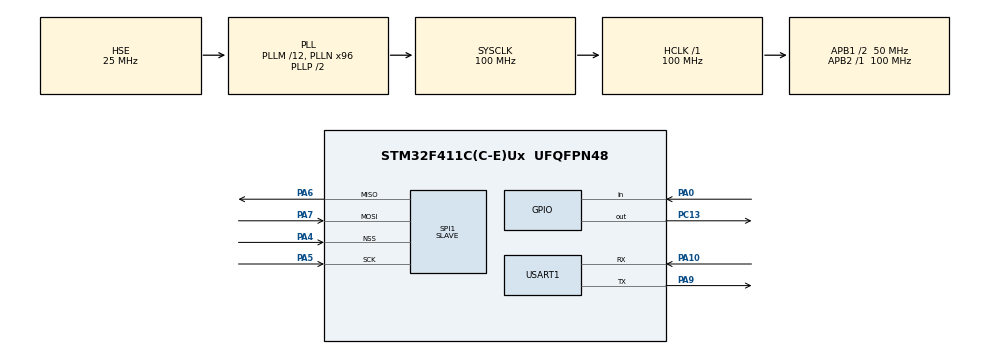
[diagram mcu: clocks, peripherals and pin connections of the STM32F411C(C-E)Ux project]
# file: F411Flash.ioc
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Mcu.Family=STM32F4
Mcu.Name=STM32F411C(C-E)Ux
Mcu.Package=UFQFPN48
NVIC.PriorityGroup=NVIC_PRIORITYGROUP_4
NVIC.TIM4_IRQn=true\:0\:0\:false\:false\:true\:true\:true\:true
PA0-WKUP.Signal=GPIO_Input
PA10.Mode=Asynchronous
PA10.Signal=USART1_RX
PA13.Mode=Serial_Wire
PA13.Signal=SYS_JTMS-SWDIO
PA14.Mode=Serial_Wire
PA14.Signal=SYS_JTCK-SWCLK
PA4.Mode=NSS_Signal_Hard_Input
PA4.Signal=SPI1_NSS
PA5.Mode=Full_Duplex_Slave
PA5.Signal=SPI1_SCK
PA6.Mode=Full_Duplex_Slave
PA6.Signal=SPI1_MISO
PA7.Mode=Full_Duplex_Slave
PA7.Signal=SPI1_MOSI
PA9.Mode=Asynchronous
PA9.Signal=USART1_TX
PC13-ANTI_TAMP.Signal=GPIO_Output
PH0\ -\ OSC_IN.Mode=HSE-External-Oscillator
PH0\ -\ OSC_IN.Signal=RCC_OSC_IN
PH1\ -\ OSC_OUT.Mode=HSE-External-Oscillator
PH1\ -\ OSC_OUT.Signal=RCC_OSC_OUT
ProjectManager.HeapSize=0x200
ProjectManager.StackSize=0x400
ProjectManager.TargetToolchain=STM32CubeIDE
RCC.48MHZClocksFreq_Value=50000000
RCC.AHBFreq_Value=100000000
RCC.APB1CLKDivider=RCC_HCLK_DIV2
RCC.APB1Freq_Value=50000000
RCC.APB1TimFreq_Value=100000000
RCC.APB2Freq_Value=100000000
RCC.APB2TimFreq_Value=100000000
RCC.CortexFreq_Value=100000000
RCC.HCLKFreq_Value=100000000
RCC.HSE_VALUE=25000000
RCC.HSI_VALUE=16000000
RCC.LSE_VALUE=32768
RCC.PLLM=12
RCC.PLLN=96
RCC.PLLSourceVirtual=RCC_PLLSOURCE_HSE
RCC.SYSCLKFreq_VALUE=100000000
RCC.SYSCLKSource=RCC_SYSCLKSOURCE_PLLCLK
RCC.VCOOutputFreq_Value=200000000
SPI1.Direction=SPI_DIRECTION_2LINES
SPI1.Mode=SPI_MODE_SLAVE
SPI1.VirtualNSS=VM_NSSHARD
SPI1.VirtualType=VM_SLAVE
TIM4.Period=1000
TIM4.Prescaler=49999
USART1.VirtualMode=VM_ASYNC
VP_TIM4_VS_ClockSourceINT.Mode=Internal
board=custom

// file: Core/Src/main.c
/* USER CODE BEGIN Header */
/**
  ******************************************************************************
  * @file           : main.c
  * @brief          : Main program body
  ******************************************************************************
  * @attention
  *
  * Copyright (c) 2025 STMicroelectronics.
  * All rights reserved.
  *
  * This software is licensed under terms that can be found in the LICENSE file
  * in the root directory of this software component.
  * If no LICENSE file comes with this software, it is provided AS-IS.
  *
  ******************************************************************************
  */
/* USER CODE END Header */
#include "main.h"

SPI_HandleTypeDef hspi1;

TIM_HandleTypeDef htim4;

UART_HandleTypeDef huart1;

void SystemClock_Config(void);
static void MX_GPIO_Init(void);
static void MX_SPI1_Init(void);
static void MX_USART1_UART_Init(void);
static void MX_TIM4_Init(void);
/* USER CODE BEGIN PFP */
void init();
void loop();
/* USER CODE END PFP */

/* USER CODE BEGIN 0 */
void init()
{
	HAL_TIM_Base_Start_IT(&htim4);
	return;
}

void loop()
{
	return;
}

/* USER CODE END 0 */

int main(void)
{

  /* MCU Configuration--------------------------------------------------------*/

  /* Reset of all peripherals, Initializes the Flash interface and the Systick. */
  HAL_Init();

  /* Configure the system clock */
  SystemClock_Config();

  /* Initialize all configured peripherals */
  MX_GPIO_Init();
  MX_SPI1_Init();
  MX_USART1_UART_Init();
  MX_TIM4_Init();

  /* Infinite loop */
  /* USER CODE BEGIN WHILE */
  init();
  while (1)
  {
	loop();
    /* USER CODE END WHILE */

  }
}

void SystemClock_Config(void)
{
  RCC_OscInitTypeDef RCC_OscInitStruct = {0};
  RCC_ClkInitTypeDef RCC_ClkInitStruct = {0};

  /** Configure the main internal regulator output voltage
  */
  __HAL_RCC_PWR_CLK_ENABLE();
  __HAL_PWR_VOLTAGESCALING_CONFIG(PWR_REGULATOR_VOLTAGE_SCALE1);

  /** Initializes the RCC Oscillators according to the specified parameters
  * in the RCC_OscInitTypeDef structure.
  */
  RCC_OscInitStruct.OscillatorType = RCC_OSCILLATORTYPE_HSE;
  RCC_OscInitStruct.HSEState = RCC_HSE_ON;
  RCC_OscInitStruct.PLL.PLLState = RCC_PLL_ON;
  RCC_OscInitStruct.PLL.PLLSource = RCC_PLLSOURCE_HSE;
  RCC_OscInitStruct.PLL.PLLM = 12;
  RCC_OscInitStruct.PLL.PLLN = 96;
  RCC_OscInitStruct.PLL.PLLP = RCC_PLLP_DIV2;
  RCC_OscInitStruct.PLL.PLLQ = 4;
  if (HAL_RCC_OscConfig(&RCC_OscInitStruct) != HAL_OK)
  {
    Error_Handler();
  }

  /** Initializes the CPU, AHB and APB buses clocks
  */
  RCC_ClkInitStruct.ClockType = RCC_CLOCKTYPE_HCLK|RCC_CLOCKTYPE_SYSCLK
                              |RCC_CLOCKTYPE_PCLK1|RCC_CLOCKTYPE_PCLK2;
  RCC_ClkInitStruct.SYSCLKSource = RCC_SYSCLKSOURCE_PLLCLK;
  RCC_ClkInitStruct.AHBCLKDivider = RCC_SYSCLK_DIV1;
  RCC_ClkInitStruct.APB1CLKDivider = RCC_HCLK_DIV2;
  RCC_ClkInitStruct.APB2CLKDivider = RCC_HCLK_DIV1;

  if (HAL_RCC_ClockConfig(&RCC_ClkInitStruct, FLASH_LATENCY_3) != HAL_OK)
  {
    Error_Handler();
  }
}

static void MX_SPI1_Init(void)
{

  /* SPI1 parameter configuration*/
  hspi1.Instance = SPI1;
  hspi1.Init.Mode = SPI_MODE_SLAVE;
  hspi1.Init.Direction = SPI_DIRECTION_2LINES;
  hspi1.Init.DataSize = SPI_DATASIZE_8BIT;
  hspi1.Init.CLKPolarity = SPI_POLARITY_LOW;
  hspi1.Init.CLKPhase = SPI_PHASE_1EDGE;
  hspi1.Init.NSS = SPI_NSS_HARD_INPUT;
  hspi1.Init.FirstBit = SPI_FIRSTBIT_MSB;
  hspi1.Init.TIMode = SPI_TIMODE_DISABLE;
  hspi1.Init.CRCCalculation = SPI_CRCCALCULATION_DISABLE;
  hspi1.Init.CRCPolynomial = 10;
  if (HAL_SPI_Init(&hspi1) != HAL_OK)
  {
    Error_Handler();
  }

}

static void MX_TIM4_Init(void)
{

  TIM_ClockConfigTypeDef sClockSourceConfig = {0};
  TIM_MasterConfigTypeDef sMasterConfig = {0};

  htim4.Instance = TIM4;
  htim4.Init.Prescaler = 49999;
  htim4.Init.CounterMode = TIM_COUNTERMODE_UP;
  htim4.Init.Period = 1000;
  htim4.Init.ClockDivision = TIM_CLOCKDIVISION_DIV1;
  htim4.Init.AutoReloadPreload = TIM_AUTORELOAD_PRELOAD_DISABLE;
  if (HAL_TIM_Base_Init(&htim4) != HAL_OK)
  {
    Error_Handler();
  }
  sClockSourceConfig.ClockSource = TIM_CLOCKSOURCE_INTERNAL;
  if (HAL_TIM_ConfigClockSource(&htim4, &sClockSourceConfig) != HAL_OK)
  {
    Error_Handler();
  }
  sMasterConfig.MasterOutputTrigger = TIM_TRGO_RESET;
  sMasterConfig.MasterSlaveMode = TIM_MASTERSLAVEMODE_DISABLE;
  if (HAL_TIMEx_MasterConfigSynchronization(&htim4, &sMasterConfig) != HAL_OK)
  {
    Error_Handler();
  }

}

static void MX_USART1_UART_Init(void)
{

  huart1.Instance = USART1;
  huart1.Init.BaudRate = 115200;
  huart1.Init.WordLength = UART_WORDLENGTH_8B;
  huart1.Init.StopBits = UART_STOPBITS_1;
  huart1.Init.Parity = UART_PARITY_NONE;
  huart1.Init.Mode = UART_MODE_TX_RX;
  huart1.Init.HwFlowCtl = UART_HWCONTROL_NONE;
  huart1.Init.OverSampling = UART_OVERSAMPLING_16;
  if (HAL_UART_Init(&huart1) != HAL_OK)
  {
    Error_Handler();
  }

}

static void MX_GPIO_Init(void)
{
  GPIO_InitTypeDef GPIO_InitStruct = {0};

  /* GPIO Ports Clock Enable */
  __HAL_RCC_GPIOC_CLK_ENABLE();
  __HAL_RCC_GPIOH_CLK_ENABLE();
  __HAL_RCC_GPIOA_CLK_ENABLE();

  /*Configure GPIO pin Output Level */
  HAL_GPIO_WritePin(GPIOC, GPIO_PIN_13, GPIO_PIN_RESET);

  /*Configure GPIO pin : PC13 */
  GPIO_InitStruct.Pin = GPIO_PIN_13;
  GPIO_InitStruct.Mode = GPIO_MODE_OUTPUT_PP;
  GPIO_InitStruct.Pull = GPIO_NOPULL;
  GPIO_InitStruct.Speed = GPIO_SPEED_FREQ_LOW;
  HAL_GPIO_Init(GPIOC, &GPIO_InitStruct);

  /*Configure GPIO pin : PA0 */
  GPIO_InitStruct.Pin = GPIO_PIN_0;
  GPIO_InitStruct.Mode = GPIO_MODE_INPUT;
  GPIO_InitStruct.Pull = GPIO_NOPULL;
  HAL_GPIO_Init(GPIOA, &GPIO_InitStruct);

}

/* USER CODE BEGIN 4 */
void HAL_TIM_PeriodElapsedCallback(TIM_HandleTypeDef *htim)
{
  if (htim->Instance == TIM4)
  {
	HAL_GPIO_TogglePin(GPIOC, GPIO_PIN_13);
  }
}
/* USER CODE END 4 */

void Error_Handler(void)
{
  __disable_irq();
  while (1)
  {
  }
}
